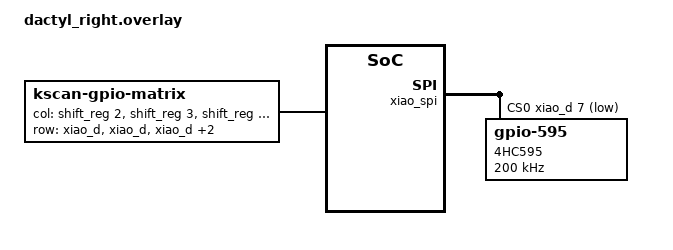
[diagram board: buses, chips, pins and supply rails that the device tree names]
#include "dactyl.dtsi"

&default_transform { // The matrix transform for this board is 6 columns over because the left half is 6 columns wide according to the matrix.
    col-offset = <6>;
};

#include <dt-bindings/zmk/matrix_transform.h>


/ {

   chosen {
     zmk,kscan = &kscan;
   };

   kscan: kscan {
     compatible = "zmk,kscan-gpio-matrix";
     label = "kscan";
     diode-direction = "col2row";
     col-gpios =   <&shift_reg 2 (GPIO_ACTIVE_HIGH)>
                 , <&shift_reg 3 (GPIO_ACTIVE_HIGH)>
                 , <&shift_reg 4 (GPIO_ACTIVE_HIGH)>
                 , <&shift_reg 5 (GPIO_ACTIVE_HIGH)>
                 , <&shift_reg 6 (GPIO_ACTIVE_HIGH)>
                 , <&shift_reg 7 (GPIO_ACTIVE_HIGH)>
                 ;
     row-gpios = <&xiao_d 0(GPIO_ACTIVE_HIGH | GPIO_PULL_DOWN)>
                 ,<&xiao_d 1(GPIO_ACTIVE_HIGH | GPIO_PULL_DOWN)>
                 ,<&xiao_d 2(GPIO_ACTIVE_HIGH | GPIO_PULL_DOWN)>
                 ,<&xiao_d 3(GPIO_ACTIVE_HIGH | GPIO_PULL_DOWN)>
                 ,<&xiao_d 4(GPIO_ACTIVE_HIGH | GPIO_PULL_DOWN)>
                 ;
   };
};

&xiao_spi {
  status = "okay";

  cs-gpios = <&xiao_d 7 GPIO_ACTIVE_LOW>;
  shift_reg: 595@0 {
    compatible = "zmk,gpio-595";
    status = "okay";
    gpio-controller;
    spi-max-frequency = <200000>;
    #gpio-cells = <2>;
    reg = <0>;
    label = "4HC595";
    ngpios = <16>;
  };
};

&xiao_serial { 
  status = "disabled"; 
};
